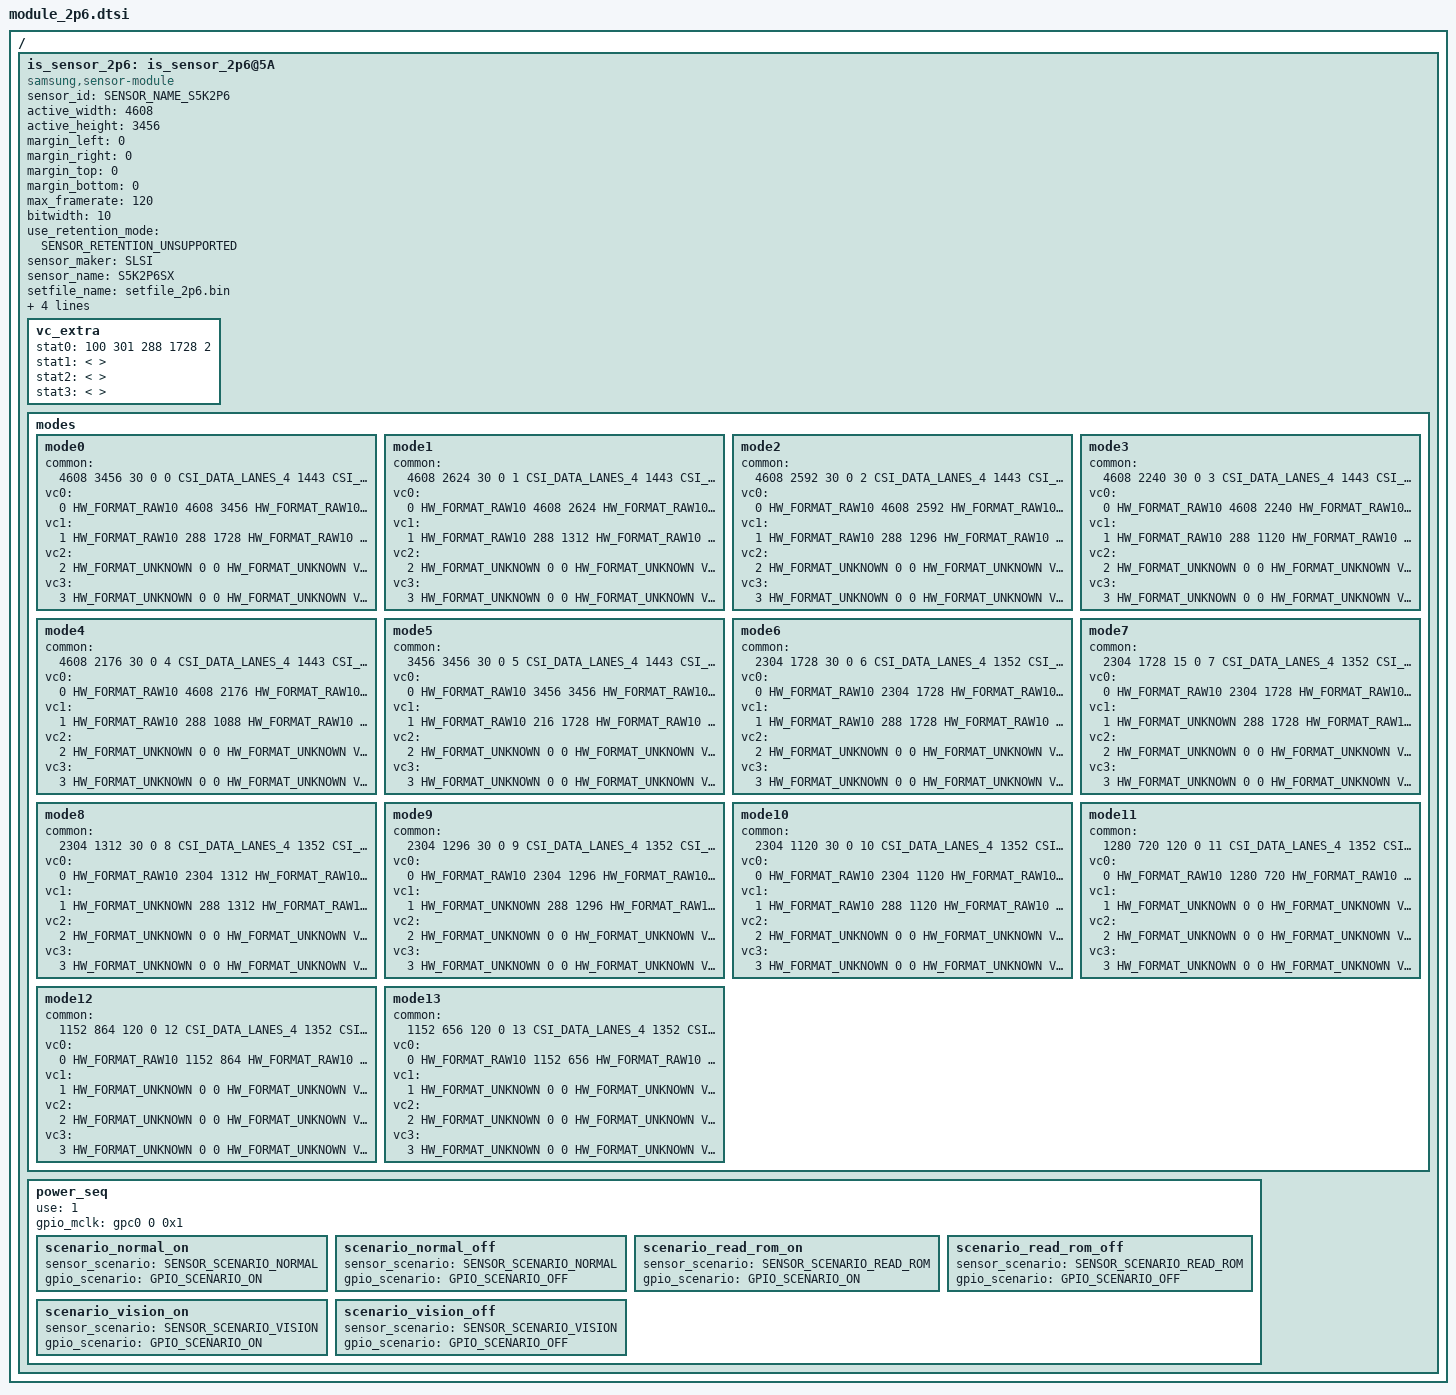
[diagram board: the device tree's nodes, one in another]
/*
 * SAMSUNG EXYNOSxxxx board camera device tree source
 *
 * Copyright (c) 2020 Samsung Electronics Co., Ltd.
 *        http://www.samsung.com
 *
 * This program is free software; you can redistribute it and/or modify
 * it under the terms of the GNU General Public License version 2 as
 * published by the Free Software Foundation.
 */

#include <dt-bindings/camera/exynos_is_dt.h>

#ifndef USE_VENDOR_PWR_PIN_NAME
#define RCAM_AF_VDD		<>		/* RCAM_AFVDD_2P8 - VLDO32*/
#define S5K2P6_AVDD		<>		/* RCAM_AVDD : RCAM_AVDD_LDO_EN - RCAM_LDO_EN*/
#define S5K2P6_DVDD		<>		/* RCAM_DVDD_1P05 - VLDO29*/
#define S5K2P6_IOVDD	<>		/* CAM_VDDIO_1P8 - RCAM_VDDIO_LDO_EN */
#define S5K2P6_RST		<>		/* RCAM_RST_N */
#endif

/ {
	fragment@camera {
		target-path = "/";
		__overlay__ {
			is_sensor_2p6: is_sensor_2p6@5A {
				compatible = "samsung,sensor-module";

				/* common */
				sensor_id = <SENSOR_NAME_S5K2P6>;
				active_width = <4608>;
				active_height = <3456>;
				margin_left = <0>;
				margin_right = <0>;
				margin_top = <0>;
				margin_bottom = <0>;
				max_framerate = <120>;
				bitwidth = <10>;
				use_retention_mode = <SENSOR_RETENTION_UNSUPPORTED>;
				sensor_maker = "SLSI";
				sensor_name = "S5K2P6SX";
				setfile_name = "setfile_2p6.bin";

				rcam_af_vdd-supply = RCAM_AF_VDD;
				2p6_avdd-supply = S5K2P6_AVDD;
				2p6_dvdd-supply = S5K2P6_DVDD;
				2p6_iovdd-supply = S5K2P6_IOVDD;

				status = "okay";

				vc_extra {
					/* ex) statX = <stat_type, sensor_mode, max_width, max_height, max_element> */
					stat0 = </* VC_STAT_TYPE_TAIL_FOR_SW_PDAF */ 100 /* VC_SENSOR_MODE_ULTRA_PD_TAIL */ 301 288 1728 2>;	/* VC_BUF_DATA_TYPE_SENSOR_STAT1 */
					stat1 = </* not avaliable */>;	/* VC_BUF_DATA_TYPE_GENERAL_STAT1 */
					stat2 = </* not avaliable */>;	/* VC_BUF_DATA_TYPE_SENSOR_STAT2 */
					stat3 = </* not avaliable */>;	/* VC_BUF_DATA_TYPE_GENERAL_STAT2 */
				};

				/* sensor modes */
				modes {
						/* common = <width, height, fps, settle, mode, lane, speed, interleave, lrte, pd_mode> */
						/* vcX = <map, hwformat, width, height, hwformat, type, width, height> */
					mode0 {
						common = <4608 3456 30 0 0 CSI_DATA_LANES_4 1443 CSI_MODE_VC_ONLY LRTE_DISABLE PD_MSPD_TAIL EX_NONE>;
						vc0 = </* in */ 0 HW_FORMAT_RAW10 4608 3456	/* out */ HW_FORMAT_RAW10 VC_NOTHING 0 0>;
						vc1 = </* in */ 1 HW_FORMAT_RAW10 288  1728	/* out */ HW_FORMAT_RAW10 VC_TAILPDAF 288 1728>;
						vc2 = </* in */ 2 HW_FORMAT_UNKNOWN 0 0		/* out */ HW_FORMAT_UNKNOWN VC_NOTHING 0 0>;
						vc3 = </* in */ 3 HW_FORMAT_UNKNOWN 0 0		/* out */ HW_FORMAT_UNKNOWN VC_NOTHING 0 0>;
					};
					mode1 {
						common = <4608 2624 30 0 1 CSI_DATA_LANES_4 1443 CSI_MODE_VC_ONLY LRTE_DISABLE PD_MSPD_TAIL EX_NONE>;
						vc0 = <0 HW_FORMAT_RAW10 4608 2624	/* out */ HW_FORMAT_RAW10 VC_NOTHING 0 0>;
						vc1 = <1 HW_FORMAT_RAW10 288  1312	/* out */ HW_FORMAT_RAW10 VC_TAILPDAF 288 1312>;
						vc2 = <2 HW_FORMAT_UNKNOWN 0 0		/* out */ HW_FORMAT_UNKNOWN VC_NOTHING 0 0>;
						vc3 = <3 HW_FORMAT_UNKNOWN 0 0		/* out */ HW_FORMAT_UNKNOWN VC_NOTHING 0 0>;
					};
					mode2 {
						common = <4608 2592 30 0 2 CSI_DATA_LANES_4 1443 CSI_MODE_VC_ONLY LRTE_DISABLE PD_MSPD_TAIL EX_NONE>;
						vc0 = <0 HW_FORMAT_RAW10 4608 2592	/* out */ HW_FORMAT_RAW10 VC_NOTHING 0 0>;
						vc1 = <1 HW_FORMAT_RAW10 288  1296	/* out */ HW_FORMAT_RAW10 VC_TAILPDAF 288  1296>;
						vc2 = <2 HW_FORMAT_UNKNOWN 0 0		/* out */ HW_FORMAT_UNKNOWN VC_NOTHING 0 0>;
						vc3 = <3 HW_FORMAT_UNKNOWN 0 0		/* out */ HW_FORMAT_UNKNOWN VC_NOTHING 0 0>;
					};
					mode3 {
						common = <4608 2240 30 0 3 CSI_DATA_LANES_4 1443 CSI_MODE_VC_ONLY LRTE_DISABLE PD_MSPD_TAIL EX_NONE>;
						vc0 = <0 HW_FORMAT_RAW10 4608 2240	/* out */ HW_FORMAT_RAW10 VC_NOTHING 0 0>;
						vc1 = <1 HW_FORMAT_RAW10 288  1120	/* out */ HW_FORMAT_RAW10 VC_TAILPDAF 288 1120>;
						vc2 = <2 HW_FORMAT_UNKNOWN 0 0		/* out */ HW_FORMAT_UNKNOWN VC_NOTHING 0 0>;
						vc3 = <3 HW_FORMAT_UNKNOWN 0 0		/* out */ HW_FORMAT_UNKNOWN VC_NOTHING 0 0>;
					};
					mode4 {
						common = <4608 2176 30 0 4 CSI_DATA_LANES_4 1443 CSI_MODE_VC_ONLY LRTE_DISABLE PD_MSPD_TAIL EX_NONE>;
						vc0 = <0 HW_FORMAT_RAW10 4608 2176	/* out */ HW_FORMAT_RAW10 VC_NOTHING 0 0>;
						vc1 = <1 HW_FORMAT_RAW10 288  1088	/* out */ HW_FORMAT_RAW10 VC_TAILPDAF 288 1088>;
						vc2 = <2 HW_FORMAT_UNKNOWN 0 0		/* out */ HW_FORMAT_UNKNOWN VC_NOTHING 0 0>;
						vc3 = <3 HW_FORMAT_UNKNOWN 0 0		/* out */ HW_FORMAT_UNKNOWN VC_NOTHING 0 0>;
					};
					mode5 {
						common = <3456 3456 30 0 5 CSI_DATA_LANES_4 1443 CSI_MODE_VC_ONLY LRTE_DISABLE PD_MSPD_TAIL EX_NONE>;
						vc0 = <0 HW_FORMAT_RAW10 3456 3456	/* out */ HW_FORMAT_RAW10 VC_NOTHING 0 0>;
						vc1 = <1 HW_FORMAT_RAW10 216  1728	/* out */ HW_FORMAT_RAW10 VC_TAILPDAF 216 1728>;
						vc2 = <2 HW_FORMAT_UNKNOWN 0 0		/* out */ HW_FORMAT_UNKNOWN VC_NOTHING 0 0>;
						vc3 = <3 HW_FORMAT_UNKNOWN 0 0		/* out */ HW_FORMAT_UNKNOWN VC_NOTHING 0 0>;
					};
					mode6 {
						common = <2304 1728 30 0 6 CSI_DATA_LANES_4 1352 CSI_MODE_VC_ONLY LRTE_DISABLE PD_MSPD_TAIL EX_NONE>;
						vc0 = <0 HW_FORMAT_RAW10 2304 1728	/* out */ HW_FORMAT_RAW10 VC_NOTHING 0 0>;
						vc1 = <1 HW_FORMAT_RAW10 288  1728	/* out */ HW_FORMAT_RAW10 VC_TAILPDAF 288 1728>;
						vc2 = <2 HW_FORMAT_UNKNOWN 0 0		/* out */ HW_FORMAT_UNKNOWN VC_NOTHING 0 0>;
						vc3 = <3 HW_FORMAT_UNKNOWN 0 0		/* out */ HW_FORMAT_UNKNOWN VC_NOTHING 0 0>;
					};
					mode7 {
						common = <2304 1728 15 0 7 CSI_DATA_LANES_4 1352 CSI_MODE_VC_ONLY LRTE_DISABLE PD_MSPD_TAIL EX_NONE>;
						vc0 = <0 HW_FORMAT_RAW10 2304 1728	/* out */ HW_FORMAT_RAW10 VC_NOTHING 0 0>;
						vc1 = <1 HW_FORMAT_UNKNOWN 288 1728	/* out */ HW_FORMAT_RAW10 VC_TAILPDAF 288 1728>;
						vc2 = <2 HW_FORMAT_UNKNOWN 0 0		/* out */ HW_FORMAT_UNKNOWN VC_NOTHING 0 0>;
						vc3 = <3 HW_FORMAT_UNKNOWN 0 0		/* out */ HW_FORMAT_UNKNOWN VC_NOTHING 0 0>;
					};
					mode8 {
						common = <2304 1312 30 0 8 CSI_DATA_LANES_4 1352 CSI_MODE_VC_ONLY LRTE_DISABLE PD_MSPD_TAIL EX_NONE>;
						vc0 = <0 HW_FORMAT_RAW10 2304 1312	/* out */ HW_FORMAT_RAW10 VC_NOTHING 0 0>;
						vc1 = <1 HW_FORMAT_UNKNOWN 288 1312	/* out */ HW_FORMAT_RAW10 VC_TAILPDAF 288 1312>;
						vc2 = <2 HW_FORMAT_UNKNOWN 0 0		/* out */ HW_FORMAT_UNKNOWN VC_NOTHING 0 0>;
						vc3 = <3 HW_FORMAT_UNKNOWN 0 0		/* out */ HW_FORMAT_UNKNOWN VC_NOTHING 0 0>;
					};
					mode9 {
						common = <2304 1296 30 0 9 CSI_DATA_LANES_4 1352 CSI_MODE_VC_ONLY LRTE_DISABLE PD_MSPD_TAIL EX_NONE>;
						vc0 = <0 HW_FORMAT_RAW10 2304 1296	/* out */ HW_FORMAT_RAW10 VC_NOTHING 0 0>;
						vc1 = <1 HW_FORMAT_UNKNOWN 288  1296	/* out */ HW_FORMAT_RAW10 VC_TAILPDAF 288  1296>;
						vc2 = <2 HW_FORMAT_UNKNOWN 0 0		/* out */ HW_FORMAT_UNKNOWN VC_NOTHING 0 0>;
						vc3 = <3 HW_FORMAT_UNKNOWN 0 0		/* out */ HW_FORMAT_UNKNOWN VC_NOTHING 0 0>;
					};
					mode10 {
						common = <2304 1120 30 0 10 CSI_DATA_LANES_4 1352 CSI_MODE_VC_ONLY LRTE_DISABLE PD_MSPD_TAIL EX_NONE>;
						vc0 = <0 HW_FORMAT_RAW10 2304 1120	/* out */ HW_FORMAT_RAW10 VC_NOTHING 0 0>;
						vc1 = <1 HW_FORMAT_RAW10 288  1120	/* out */ HW_FORMAT_RAW10 VC_TAILPDAF 288 1120>;
						vc2 = <2 HW_FORMAT_UNKNOWN 0 0		/* out */ HW_FORMAT_UNKNOWN VC_NOTHING 0 0>;
						vc3 = <3 HW_FORMAT_UNKNOWN 0 0		/* out */ HW_FORMAT_UNKNOWN VC_NOTHING 0 0>;
					};
					mode11 {
						common = <1280 720 120 0 11 CSI_DATA_LANES_4 1352 CSI_MODE_VC_ONLY LRTE_DISABLE PD_NONE EX_NONE>;
						vc0 = <0 HW_FORMAT_RAW10 1280 720	/* out */ HW_FORMAT_RAW10 VC_NOTHING 0 0>;
						vc1 = <1 HW_FORMAT_UNKNOWN 0  0	/* out */ HW_FORMAT_UNKNOWN VC_NOTHING 0 0>;
						vc2 = <2 HW_FORMAT_UNKNOWN 0 0		/* out */ HW_FORMAT_UNKNOWN VC_NOTHING 0 0>;
						vc3 = <3 HW_FORMAT_UNKNOWN 0 0		/* out */ HW_FORMAT_UNKNOWN VC_NOTHING 0 0>;
					};
                    mode12 {
						common = <1152 864 120 0 12 CSI_DATA_LANES_4 1352 CSI_MODE_VC_ONLY LRTE_DISABLE PD_NONE EX_NONE>;
						vc0 = <0 HW_FORMAT_RAW10 1152 864	/* out */ HW_FORMAT_RAW10 VC_NOTHING 0 0>;
						vc1 = <1 HW_FORMAT_UNKNOWN 0  0		/* out */ HW_FORMAT_UNKNOWN VC_NOTHING 0 0>;
						vc2 = <2 HW_FORMAT_UNKNOWN 0 0		/* out */ HW_FORMAT_UNKNOWN VC_NOTHING 0 0>;
						vc3 = <3 HW_FORMAT_UNKNOWN 0 0		/* out */ HW_FORMAT_UNKNOWN VC_NOTHING 0 0>;
					};
                    mode13 {
						common = <1152 656 120 0 13 CSI_DATA_LANES_4 1352 CSI_MODE_VC_ONLY LRTE_DISABLE PD_NONE EX_NONE>;
						vc0 = <0 HW_FORMAT_RAW10 1152 656	/* out */ HW_FORMAT_RAW10 VC_NOTHING 0 0>;
						vc1 = <1 HW_FORMAT_UNKNOWN 0  0		/* out */ HW_FORMAT_UNKNOWN VC_NOTHING 0 0>;
						vc2 = <2 HW_FORMAT_UNKNOWN 0 0		/* out */ HW_FORMAT_UNKNOWN VC_NOTHING 0 0>;
						vc3 = <3 HW_FORMAT_UNKNOWN 0 0		/* out */ HW_FORMAT_UNKNOWN VC_NOTHING 0 0>;
					};
				};

				power_seq {
					use = <1>;
					gpio_mclk = <&gpc0 0 0x1>;

					scenario_normal_on {
						sensor_scenario = <SENSOR_SCENARIO_NORMAL>;
						gpio_scenario = <GPIO_SCENARIO_ON>;

						/* A start node number should be over the 10 for reserved number 0~9. */
						/* pname = "name"; pin = <act value delay voltage>; gpio = <gpx# # 0x1>; */				
					};

					scenario_normal_off {
						sensor_scenario = <SENSOR_SCENARIO_NORMAL>;
						gpio_scenario = <GPIO_SCENARIO_OFF>;

						/* A start node number should be over the 10 for reserved number 0~9. */
						/* pname = "name"; pin = <act value delay voltage>;	gpio = <gpx# # 0x1>; */
					};

					scenario_read_rom_on {
						sensor_scenario = <SENSOR_SCENARIO_READ_ROM>;
						gpio_scenario = <GPIO_SCENARIO_ON>;
					};

					scenario_read_rom_off {
						sensor_scenario = <SENSOR_SCENARIO_READ_ROM>;
						gpio_scenario = <GPIO_SCENARIO_OFF>;
					};

					scenario_vision_on {
						sensor_scenario = <SENSOR_SCENARIO_VISION>;
						gpio_scenario = <GPIO_SCENARIO_ON>;

						/* A start node number should be over the 10 for reserved number 0~9. */
						/* pname = "name"; pin = <act value delay voltage>; gpio = <gpx# # 0x1>; */
					};

					scenario_vision_off {
						sensor_scenario = <SENSOR_SCENARIO_VISION>;
						gpio_scenario = <GPIO_SCENARIO_OFF>;

						/* A start node number should be over the 10 for reserved number 0~9. */
						/* pname = "name"; pin = <act value delay voltage>; gpio = <gpx# # 0x1>; */
					};
				};
			};
		}; /* end of __overlay__ */
	}; /* end of fragment */
}; /* end of root */
